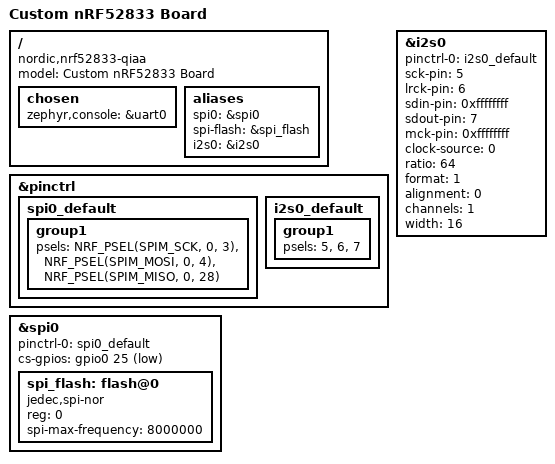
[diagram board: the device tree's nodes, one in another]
// custom_nrf52833.dts

/dts-v1/;
#include <nordic/nrf52833_qiaa.dtsi>

/ {
    model = "Custom nRF52833 Board";
    compatible = "nordic,nrf52833-qiaa";

    chosen {
        zephyr,console = &uart0;
    };

    aliases {
        spi0 = &spi0;
        spi-flash = &spi_flash;
        i2s0 = &i2s0;
    };
};

&pinctrl {
    spi0_default: spi0_default {
        group1 {
            psels = <NRF_PSEL(SPIM_SCK, 0, 3)>,   // P0.03 for SCK
                    <NRF_PSEL(SPIM_MOSI, 0, 4)>,  // P0.04 for MOSI
                    <NRF_PSEL(SPIM_MISO, 0, 28)>; // P0.28 for MISO
        };
    };

    i2s0_default: i2s0_default {
        group1 {
            psels = <5>,   // P0.05 for SCK
                    <6>,   // P0.06 for LRCK
                    <7>;   // P0.07 for SDOUT
        };
    };
};

&spi0 {
    status = "okay";
    pinctrl-0 = <&spi0_default>;
    pinctrl-names = "default";

    cs-gpios = <&gpio0 25 GPIO_ACTIVE_LOW>; // CS (P0.25)

    spi_flash: flash@0 {
        compatible = "jedec,spi-nor";
        reg = <0>;
        spi-max-frequency = <8000000>; // Adjust as needed
    };
};

&i2s0 {
    status = "okay";
    pinctrl-0 = <&i2s0_default>;
    pinctrl-names = "default";

    sck-pin = <5>;         // P0.05
    lrck-pin = <6>;        // P0.06
    sdin-pin = <0xffffffff>; // Not used
    sdout-pin = <7>;       // P0.07
    mck-pin = <0xffffffff>;  // Not used
    clock-source = <0>;    // Optional: Remove if not required
    ratio = <64>;          // I2S ratio (64x)
    format = <1>;          // Standard I2S format
    alignment = <0>;       // Left alignment
    channels = <1>;        // Single channel (left)
    width = <16>;          // 16-bit word size
};
